# STM32H730xx register map
File version: 1.0
Registers are 32-bit, access not given, reset 0x0 unless marked. A register's access mark holds for its fields unless they carry their own. Offsets are from the block's base; [hi:lo] are bit positions; {n}, {i} and the like mark numbered series.

## OCTOSPIM
Base 0x5200B400
0x00 CR
  [26:25] IOHSRC, [26:25] IOHSRC, [26:25] IOHSRC, [24] IOHEN, [24] IOHEN, [24] IOHEN, [18:17] IOLSRC, [18:17] IOLSRC, [18:17] IOLSRC, [23:16] REQ2ACK_TIME, [16] IOLEN, [16] IOLEN, [16] IOLEN, [9] NCSSRC, [9] NCSSRC, [9] NCSSRC, [8] NCSEN, [8] NCSEN, [8] NCSEN, [5] DQSSRC, [5] DQSSRC, [5] DQSSRC, [4] DQSEN, [4] DQSEN, [4] DQSEN, [1] CLKSRC, [1] CLKSRC, [1] CLKSRC, [0] MUXEN, [0] CLKEN, [0] CLKEN, [0] CLKEN
0x04 PCR.0
0x08 PCR.1
0x0C PCR.2

## OTFDEC1
Base 0x5200B800
Same registers: OTFDEC2 0x5200BC00
0x00 CR
  [2] KEIF, [2] KEIF, [2] KEIE, [1] XONEIF, [1] XONEIF, [1] XONEIE, [0] ENC, [0] SEIF, [0] SEIF, [0] SEIE
0x300 ISR
0x304 ICR
0x308 IER
0x3EC HWCFGR2
0x3F0 HWCFGR1
0x3F4 VERR
0x3F8 IPIDR
0x3FC SIDR

## OTFDEC1_REGION1
Base 0x5200B820
Same registers: OTFDEC1_REGION2 0x5200B850, OTFDEC1_REGION3 0x5200B880, OTFDEC1_REGION4 0x5200B8B0, OTFDEC2_REGION1 0x5200BC20, OTFDEC2_REGION2 0x5200BC50, OTFDEC2_REGION3 0x5200BC80, OTFDEC2_REGION4 0x5200BCB0
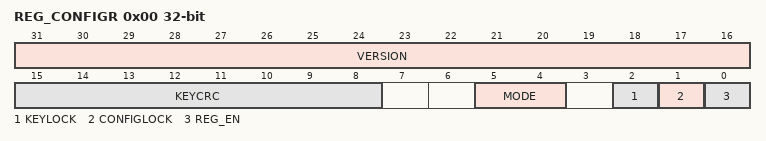
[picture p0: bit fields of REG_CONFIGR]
0x00 REG_CONFIGR
  [31:16] VERSION, [15:8] KEYCRC, [5:4] MODE, [2] KEYLOCK, [1] CONFIGLOCK, [0] REG_EN
0x04 REG_START_ADDR
0x08 REG_END_ADDR
0x0C REG_NONCER0
0x10 REG_NONCER1
{0x14+4i} REG_KEYR{i} (i=0..3)

## EXTI
Base 0x58000000
0x00 RTSR1
  [n] IM{n} (n=0..31), [n] EM{n} (n=20..31), [n-32] IM{n} (n=60..63), [n-32] EM{n} (n=60..63), [2n+1:2n] PCS{n} (n=0..15), [n-64] IM{n} (n=85..91), [n-64] EM{n} (n=85..91), [26] IM58, [26] EM58, [24] MR25, [24] MR88, [n-32] IM{n} (n=47..56), [n-32] EM{n} (n=47..56), [22] TR86, [22] TR86, [22] SWIER86, [22] PR86, [21] TR21, [21] TR21, [n] SWIER{n} (n=0..21), [21] MR21, [n-32] MR{n} (n=48..53), [21] TR85, [21] TR85, [21] SWIER85, [n] PR{n} (n=0..21), [21] PR85, [20] TR20, [20] TR20, [20] MR20, [20] PR84, [19] TR19, [19] TR19, [19] MR19, [19] TR51, [19] TR51, [19] SWIER51, [19] PR51, [18] TR18, [18] TR18, [19:18] PCS25, [19:18] PCS41, [n] EM{n} (n=0..18), [17] TR17, [17] TR17, [17] TR49, [17] TR49, [17] SWIER49, [17] PR49, [16] TR16, [16] TR16, [17:16] PCS88, [16] IM80, [16] EM80, [15] TR15, [15] TR15, [n] MR{n} (n=0..15), [14] TR14, [14] TR14, [n-64] IM{n} (n=64..78), [n-64] EM{n} (n=64..78), [13] TR13, [13] TR13, [12] TR12, [12] TR12, [11] TR11, [11] TR11, [n-32] IM{n} (n=32..43), [n-32] EM{n} (n=32..43), [10] TR10, [10] TR10, [11:10] PCS21, [2n-95:2n-96] PCS{n} (n=48..53), [9] TR9, [9] TR9, [9] MR41, [8] TR8, [8] TR8, [9:8] PCS20, [7] TR7, [7] TR7, [6] TR6, [6] TR6, [7:6] PCS19, [7:6] PCS35, [5] TR5, [5] TR5, [4] TR4, [4] TR4, [5:4] PCS34, [3] TR3, [3] TR3, [3] MR35, [2] TR2, [2] TR2, [2] MR34, [1] TR1, [1] TR1, [0] TR0, [0] TR0
0x04 FTSR1
0x08 SWIER1
0x0C D3PMR1
0x10 D3PCR1L
0x14 D3PCR1H
0x20 RTSR2
0x24 FTSR2
0x28 SWIER2
0x2C D3PMR2
0x30 D3PCR2L
0x34 D3PCR2H
0x40 RTSR3
0x44 FTSR3
0x48 SWIER3
0x4C D3PMR3
0x50 D3PCR3L
0x54 D3PCR3H
{0x70+0x10*i} IMR{i} (i=1..3)
{0x74+0x10*i} EMR{i} (i=1..3)
{0x78+0x10*i} PR{i} (i=1..3)

## EXTI_D1
Base 0x58000080
Same registers: EXTI_D2 0x580000C0
0x00 IMR1
  [n] IM{n} (n=0..31), [n] EM{n} (n=20..31), [n-32] IM{n} (n=60..63), [n-32] EM{n} (n=60..63), [n-64] IM{n} (n=85..91), [n-64] EM{n} (n=85..91), [26] IM58, [26] EM58, [n-32] IM{n} (n=47..56), [n-32] EM{n} (n=47..56), [22] PR86, [n] PR{n} (n=0..21), [21] PR85, [20] PR84, [19] PR51, [n] EM{n} (n=0..18), [17] PR49, [16] IM80, [16] EM80, [n-64] IM{n} (n=64..78), [n-64] EM{n} (n=64..78), [n-32] IM{n} (n=32..43), [n-32] EM{n} (n=32..43)
0x04 EMR1
0x08 PR1
0x10 IMR2
0x14 EMR2
0x18 PR2
0x20 IMR3
0x24 EMR3
0x28 PR3

## SYSCFG
Base 0x58000400
0x04 PMCR
  [27] PC3SO, [26] PC2SO, [25] PA1SO, [24] PA0SO, [23:21] EPIS_SEL, [16] HSLV, [23:16] RDP, [31:16] BOOT_ADD0, [16] MEPAD_BANK1, [23:16] WRPN_BANK1, [27:16] PAEND_BANK1, [27:16] SAEND_BANK1, [16] IWDG1M, [16] SECURE, [16] D1SBRST, [16] FZIWDGSTB, [16] PKP, [17:16] TCM_AXI_CFG, [15] AXISRAML, [14] ITCML, [13] DTCML, [4n+3:4n] EXTI{n} (n=0..3), [4n-13:4n-16] EXTI{n} (n=4..7), [4n-29:4n-32] EXTI{n} (n=8..11), [4n-45:4n-48] EXTI{n} (n=12..15), [12] SRAM1L, [11] SRAM2L, [10] I2C5_FMP, [9] BOOSTVDDSEL, [9] SRAM4L, [8] BOOSTEN, [8] READY, [n-2] I2C_PB{n}_FMP (n=6..9), [7] BKRAML, [6] CM7L, [7:4] PCV, [7:4] PCC, [n-1] I2C{n}_FMP (n=1..4), [3] FLASHL, [2] PVDL, [1] CS, [1] ADC2_ROUT1, [0] EN, [3:0] NCV, [3:0] NCC, [0] ADC2_ROUT0, [3:0] PKG, [1:0] BORH, [15:0] BOOT_ADD1, [0] MESAD_BANK1, [11:0] PABEG_BANK1, [11:0] SABEG_BANK1, [1:0] SDRS, [0] D1STPRST, [0] FZIWDGSTP, [0] IOHSLV, [0] CPU_FREQ_BOOST
0x08 EXTICR.0
0x0C EXTICR.1
0x10 EXTICR.2
0x14 EXTICR.3
0x18 CFGR
0x20 CCCSR
0x24 CCVR
0x28 CCCR
0x30 ADC2ALT
0x124 PKGR
{0x300+4i} UR{i} (i=0..7)
{0x300+4i} UR{i} (i=11..18)
